AUTOSAR XML (schema 4-3-0)
standard types defined: UINT8, UINT16, UINT32, UINT64, SINT8, SINT16, SINT32, FLOAT32, FLOAT64
package /Pkg_ErrorMgrSat_2_1_B/ComponentTypes
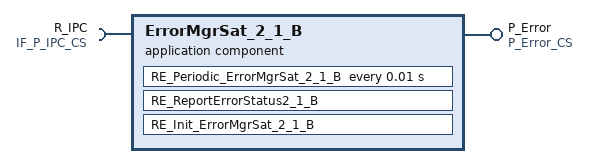
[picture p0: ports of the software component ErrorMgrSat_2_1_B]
  application sw component type ErrorMgrSat_2_1_B
    provide port P_Error: server-com-spec{operation=ReportErrorStatus2_1_B, queue-length=1}, provided-interface=P_Error_CS
    require port R_IPC: client-com-spec=IPC_Write_v, required-interface=IF_P_IPC_CS
    behavior ErrorMgrSat_2_1_B_InternalBehavior: handle-termination-and-restart=NO-SUPPORT
      timing event TMT_RE_Periodic_ErrorMgrSat_2_1_B: start-on-event=RE_Periodic_ErrorMgrSat_2_1_B, period=0.01
      operation invoked event OIT_RE_ReportErrorStatus2_1_B_P_Error_ReportErrorStatus2_1_B: start-on-event=RE_ReportErrorStatus2_1_B, operation=P_Error.ReportErrorStatus2_1_B
      init event InitEvent: start-on-event=RE_Init_ErrorMgrSat_2_1_B
      port-api-options:
        enable-take-address=false, indirect-api=false, port=P_Error
        enable-take-address=false, indirect-api=false, port=R_IPC
      runnable RE_Periodic_ErrorMgrSat_2_1_B  # Periodic Runnable of Satellite
        sync call SC_R_IPC_IPC_Write_v: operation=R_IPC.IPC_Write_v, timeout=0
      runnable RE_ReportErrorStatus2_1_B: can-be-invoked-concurrently=true  # Server Runnable for handling the error reporting
      runnable RE_Init_ErrorMgrSat_2_1_B  # Init Runnable
  swc implementation ErrorMgrSat_2_1_B_Implementation: programming-language=C, vendor-id=0, behavior=ErrorMgrSat_2_1_B_InternalBehavior
    code-descriptors:
      code Default: artifact-descriptors=autosar-engineering-object={short-label=Default, category=SWSRC}
package /Pkg_ErrorMgrSat_2_1_B/ImplementationDataTypes
  30 x impl type, all with type-emitter=RTE:
    BOOL: implementation-data-type=boolean
    ErrorMgr_ErrorField: implementation-data-type=uint8
    Error1_0QM_arr: category=ARRAY
      element Elem_ErrorMgr_ErrorField: array-size=12, array-size-semantics=FIXED-SIZE, implementation-data-type=ErrorMgr_ErrorField
    Data1_0QM_arr: category=ARRAY
      element Elem_ErrorMgr_stAddData: array-size=12, array-size-semantics=FIXED-SIZE, implementation-data-type=ErrorMgr_stAddData
    Error1_0B_arr: category=ARRAY
      element Elem_ErrorMgr_ErrorField: array-size=400, array-size-semantics=FIXED-SIZE, implementation-data-type=ErrorMgr_ErrorField
    Data1_0B_arr: category=ARRAY
      element Elem_ErrorMgr_stAddData: array-size=400, array-size-semantics=FIXED-SIZE, implementation-data-type=ErrorMgr_stAddData
    Error2_0QM_arr: category=ARRAY
      element Elem_ErrorMgr_ErrorField: array-size=1, array-size-semantics=FIXED-SIZE, implementation-data-type=ErrorMgr_ErrorField
    Padding2_0QM_arr: category=ARRAY
      element Elem_ErrorMgr_ErrorField: array-size=3, array-size-semantics=FIXED-SIZE, implementation-data-type=ErrorMgr_ErrorField
    Data2_0QM_arr: category=ARRAY
      element Elem_ErrorMgr_stAddData: array-size=1, array-size-semantics=FIXED-SIZE, implementation-data-type=ErrorMgr_stAddData
    Error2_0B_arr: category=ARRAY
      element Elem_ErrorMgr_ErrorField: array-size=144, array-size-semantics=FIXED-SIZE, implementation-data-type=ErrorMgr_ErrorField
    Data2_0B_arr: category=ARRAY
      element Elem_ErrorMgr_stAddData: array-size=144, array-size-semantics=FIXED-SIZE, implementation-data-type=ErrorMgr_stAddData
    Error2_1QM_arr: category=ARRAY
      element Elem_ErrorMgr_ErrorField: array-size=1, array-size-semantics=FIXED-SIZE, implementation-data-type=ErrorMgr_ErrorField
    Padding2_1QM_arr: category=ARRAY
      element Elem_ErrorMgr_ErrorField: array-size=3, array-size-semantics=FIXED-SIZE, implementation-data-type=ErrorMgr_ErrorField
    Data2_1QM_arr: category=ARRAY
      element Elem_ErrorMgr_stAddData: array-size=1, array-size-semantics=FIXED-SIZE, implementation-data-type=ErrorMgr_stAddData
    Error2_1B_arr: category=ARRAY
      element Elem_ErrorMgr_ErrorField: array-size=548, array-size-semantics=FIXED-SIZE, implementation-data-type=ErrorMgr_ErrorField
    Data2_1B_arr: category=ARRAY
      element Elem_ErrorMgr_stAddData: array-size=548, array-size-semantics=FIXED-SIZE, implementation-data-type=ErrorMgr_stAddData
    ErrorQNXQM_arr: category=ARRAY
      element Elem_ErrorMgr_ErrorField: array-size=1, array-size-semantics=FIXED-SIZE, implementation-data-type=ErrorMgr_ErrorField
    PaddingQNXQM_arr: category=ARRAY
      element Elem_ErrorMgr_ErrorField: array-size=3, array-size-semantics=FIXED-SIZE, implementation-data-type=ErrorMgr_ErrorField
    DataQNXQM_arr: category=ARRAY
      element Elem_ErrorMgr_stAddData: array-size=1, array-size-semantics=FIXED-SIZE, implementation-data-type=ErrorMgr_stAddData
    ErrorQNXB_arr: category=ARRAY
      element Elem_ErrorMgr_ErrorField: array-size=8, array-size-semantics=FIXED-SIZE, implementation-data-type=ErrorMgr_ErrorField
    DataQNXB_arr: category=ARRAY
      element Elem_ErrorMgr_stAddData: array-size=8, array-size-semantics=FIXED-SIZE, implementation-data-type=ErrorMgr_stAddData
    AdditionalData_arr: category=ARRAY
      element Elem_uint8: array-size=4, array-size-semantics=FIXED-SIZE, implementation-data-type=uint8
    ErrorMgr_enErrorNo: compu {556=ErrorMgr_Error_SENSOR1_OpenCkt_Fault, 557=ErrorMgr_Error_SENSOR2_OpenCkt_Fault, 558=ErrorMgr_Error_SENSOR3_OpenCkt_Fault, 559=ErrorMgr_Error_SENSOR4_OpenCkt_Fault, 560=ErrorMgr_Error_SENSOR5_OpenCkt_Fault, 561=ErrorMgr_Error_SENSOR6_OpenCkt_Fault, 562=ErrorMgr_Error_SENSOR7_OpenCkt_Fault, 563=ErrorMgr_Error_SENSOR8_OpenCkt_Fault, 564=ErrorMgr_Error_SENSOR9_OpenCkt_Fault, 565=ErrorMgr_Error_SENSOR10_OpenCkt_Fault, 566=ErrorMgr_Error_SENSOR11_OpenCkt_Fault, 567=ErrorMgr_Error_SENSOR12_OpenCkt_Fault, 568=ErrorMgr_Error_SENSOR1_USS_Power_Lost_Fault, 569=ErrorMgr_Error_SENSOR2_USS_Power_Lost_Fault, 570=ErrorMgr_Error_SENSOR3_USS_Power_Lost_Fault, 571=ErrorMgr_Error_SENSOR4_USS_Power_Lost_Fault, 572=ErrorMgr_Error_SENSOR5_USS_Power_Lost_Fault, 573=ErrorMgr_Error_SENSOR6_USS_Power_Lost_Fault, 574=ErrorMgr_Error_SENSOR7_USS_Power_Lost_Fault, 575=ErrorMgr_Error_SENSOR8_USS_Power_Lost_Fault, 576=ErrorMgr_Error_SENSOR9_USS_Power_Lost_Fault, 577=ErrorMgr_Error_SENSOR10_USS_Power_Lost_Fault, 578=ErrorMgr_Error_SENSOR11_USS_Power_Lost_Fault, 579=ErrorMgr_Error_SENSOR12_USS_Power_Lost_Fault, 580=ErrorMgr_Error_USS_M_F_short_to_GND, 581=ErrorMgr_Error_USS_M_F_voltage_OOR_Low, 582=ErrorMgr_Error_USS_M_R_short_to_GND, 583=ErrorMgr_Error_USS_M_R_voltage_OOR_Low, 584=ErrorMgr_Error_USS_Cal_Data_Fault, 585=ErrorMgr_Error_SENSOR1_USS_SWFirmWr_MisMatch, 586=ErrorMgr_Error_SENSOR2_USS_SWFirmWr_MisMatch, 587=ErrorMgr_Error_SENSOR3_USS_SWFirmWr_MisMatch, 588=ErrorMgr_Error_SENSOR4_USS_SWFirmWr_MisMatch, 589=ErrorMgr_Error_SENSOR5_USS_SWFirmWr_MisMatch, 590=ErrorMgr_Error_SENSOR6_USS_SWFirmWr_MisMatch, 591=ErrorMgr_Error_SENSOR7_USS_SWFirmWr_MisMatch, 592=ErrorMgr_Error_SENSOR8_USS_SWFirmWr_MisMatch, 593=ErrorMgr_Error_SENSOR9_USS_SWFirmWr_MisMatch, 594=ErrorMgr_Error_SENSOR10_USS_SWFirmWr_MisMatch, 595=ErrorMgr_Error_SENSOR11_USS_SWFirmWr_MisMatch, 596=ErrorMgr_Error_SENSOR12_USS_SWFirmWr_MisMatch, 597=ErrorMgr_Error_SENSOR1_USS_Sensor_Blockage, 598=ErrorMgr_Error_SENSOR2_USS_Sensor_Blockage, 599=ErrorMgr_Error_SENSOR3_USS_Sensor_Blockage, 600=ErrorMgr_Error_SENSOR4_USS_Sensor_Blockage, 601=ErrorMgr_Error_SENSOR5_USS_Sensor_Blockage, 602=ErrorMgr_Error_SENSOR6_USS_Sensor_Blockage, 603=ErrorMgr_Error_SENSOR7_USS_Sensor_Blockage, 604=ErrorMgr_Error_SENSOR8_USS_Sensor_Blockage, 605=ErrorMgr_Error_SENSOR9_USS_Sensor_Blockage, 606=ErrorMgr_Error_SENSOR10_USS_Sensor_Blockage, 607=ErrorMgr_Error_SENSOR11_USS_Sensor_Blockage, 608=ErrorMgr_Error_SENSOR12_USS_Sensor_Blockage, 609=ErrorMgr_Error_USS_M_F_Short_to_Bat, 610=ErrorMgr_Error_USS_M_F_voltage_OOR_High, 611=ErrorMgr_Error_USS_M_R_Short_to_Bat, 612=ErrorMgr_Error_USS_M_R_voltage_OOR_High, 613=ErrorMgr_Error_SysIntFault_MCU_USS_MASTER_internal_failure_RAM_BIST_failure, 614=ErrorMgr_Error_SysIntFault_MCU_USS_MASTER_internal_failure_FSM_RESET, 615=ErrorMgr_Error_SysIntFault_MCU_USS_MASTER_internal_failure_VDSIUV, 616=ErrorMgr_Error_SysIntFault_MCU_USS_MASTER_internal_failure_VCCUV, 617=ErrorMgr_Error_SysIntFault_MCU_USS_MASTER_ECU_COMM_ERR, 618=ErrorMgr_Error_SysIntFault_MCU_USS_MASTER_INTB_pin_low_CLKREF_failure, 619=ErrorMgr_Error_SysIntFault_MCU_USS_MASTER_DSI_Overtemperature_error, 620=ErrorMgr_Error_SysIntFault_MCU_USS_MASTER_DSI3_Safety_critical_registers_mismatch, 621=ErrorMgr_Error_SysIntFault_MCU_USS_MASTER_DSI_IRQ_STAT_CRC_ERR, 622=ErrorMgr_Error_SysIntFault_MCU_USS_MASTER_ECU_SPI_DMA_ERR, 623=ErrorMgr_Error_SysIntFault_MCU_USS_MASTER_ECU_CFG_SENSOR_ERR, 624=ErrorMgr_Error_SysIntFault_MCU_USS_MASTER_ECU_GPIO_INT_INITIAL_ERR, 625=ErrorMgr_Error_SysIntFault_MCU_USS_MASTER_ECU_PIN_INITIAL_ERR, 626=ErrorMgr_Error_SysIntFault_MCU_USS_MASTER_ECU_DSI_CLOCK_INITIAL_ERR, 627=ErrorMgr_Error_SysIntFault_MCU_USS_MASTER_ECU_SPI_INITIAL_ERR, 628=ErrorMgr_Error_SysIntFault_MCU_USS_MASTER_ECU_USS_POWER_ON_ERR, 629=ErrorMgr_Error_SysIntFault_MCU_USS_MASTER_ECU_DSI_RFC_ERR, 630=ErrorMgr_Error_SysIntFault_MCU_USS_MASTER_Front_OC_ERR, 631=ErrorMgr_Error_SysIntFault_MCU_USS_MASTER_Front_DSI_Undervoltage_error, 632=ErrorMgr_Error_SysIntFault_MCU_USS_MASTER_Rear_OC_ERR, 633=ErrorMgr_Error_SysIntFault_MCU_USS_MASTER_Rear_DSI_Undervoltage_error, 634=ErrorMgr_Error_SysIntFault_USS_SENSOR1_FLG_SIGNAL_PATH_FAILURE, 635=ErrorMgr_Error_SysIntFault_USS_SENSOR1_Vref_out_of_range, 636=ErrorMgr_Error_SysIntFault_USS_SENSOR1_VREF_OTP_out_of_range, 637=ErrorMgr_Error_SysIntFault_USS_SENSOR1_VDDD_out_of_range, 638=ErrorMgr_Error_SysIntFault_USS_SENSOR1_DRV1_FAILURE_DURING_BURST, 639=ErrorMgr_Error_SysIntFault_USS_SENSOR1_DRV2_FAILURE_DURING_BURST, 640=ErrorMgr_Error_SysIntFault_USS_SENSOR1_DRVS_FAILURE_DURING_BURST, 641=ErrorMgr_Error_SysIntFault_USS_SENSOR1_NOISE_DURING_BURST, 642=ErrorMgr_Error_SysIntFault_USS_SENSOR1_DSP_Config_register_mismatch, 643=ErrorMgr_Error_SysIntFault_USS_SENSOR1_CPU_Config_register_mismatch, 644=ErrorMgr_Error_SysIntFault_USS_SENSOR1_RECEIVED_COMMAND_INVALID, 645=ErrorMgr_Error_SysIntFault_USS_SENSOR1_WD_COUNTER_DESYNC, 646=ErrorMgr_Error_SysIntFault_USS_SENSOR1_WD_CLOCK_FAIL, 647=ErrorMgr_Error_SysIntFault_USS_SENSOR1_SYNCHRONISATION_COUNTER_ERROR_DETECTED, 648=ErrorMgr_Error_SysIntFault_USS_SENSOR1_GET_DRV_FREQUENCY_FAILURE, 649=ErrorMgr_Error_SysIntFault_USS_SENSOR1_RING_COMPARATOR_ZERO, 650=ErrorMgr_Error_SysIntFault_USS_SENSOR1_VTANK_overvoltage_burst_status_failure, 651=ErrorMgr_Error_SysIntFault_USS_SENSOR1_BURST_ABORT_DURING_BURST, 652=ErrorMgr_Error_SysIntFault_USS_SENSOR1_VTANK_OVERVOLTAGE, 653=ErrorMgr_Error_SysIntFault_USS_SENSOR1_VTANK_UNDERVOLTAGE, 654=ErrorMgr_Error_SysIntFault_USS_SENSOR1_VSUP_OVER_VOLTAGE, 655=ErrorMgr_Error_SysIntFault_USS_SENSOR1_VSUP_UNDER_VOLTAGE, 656=ErrorMgr_Error_SysIntFault_USS_SENSOR1_Temparature_out_of_range_error, 657=ErrorMgr_Error_SysIntFault_USS_SENSOR1_SRAM_Parity_error, 658=ErrorMgr_Error_SysIntFault_USS_SENSOR1_CRC_BLOCK_CFG1, 659=ErrorMgr_Error_SysIntFault_USS_SENSOR1_CRC_BLOCK_CFG2, 660=ErrorMgr_Error_SysIntFault_USS_SENSOR1_CRC_BLOCK_MFG1, 661=ErrorMgr_Error_SysIntFault_USS_SENSOR1_CRC_BLOCK_MFG2, 662=ErrorMgr_Error_SysIntFault_USS_SENSOR1_CRC_OP_MODE1, 663=ErrorMgr_Error_SysIntFault_USS_SENSOR1_CRC_OP_MODE2, 664=ErrorMgr_Error_SysIntFault_USS_SENSOR1_CRC_MISMATCH_IN_OTP, 665=ErrorMgr_Error_SysIntFault_USS_SENSOR1_CRC_MISTMATCH_IN_EEPROM_A1, 666=ErrorMgr_Error_SysIntFault_USS_SENSOR1_CRC_MISTMATCH_IN_EEPROM_A2, 667=ErrorMgr_Error_SysIntFault_USS_SENSOR1_BAD_RING_TIME, 668=ErrorMgr_Error_SysIntFault_USS_SENSOR1_SNR_OPMODE_ERROR, 669=ErrorMgr_Error_SysIntFault_USS_SENSOR1_SNR_SETUP_SENSOR_FAIL, 670=ErrorMgr_Error_SysIntFault_USS_SENSOR1_GET_RING_FREQUENCY_FAILURE, 671=ErrorMgr_Error_SysIntFault_USS_SENSOR1_ADA_MEASURE_TIMEOUT, 672=ErrorMgr_Error_SysIntFault_USS_SENSOR1_PROGRAM_EEPROM, 673=ErrorMgr_Error_SysIntFault_USS_SENSOR2_FLG_SIGNAL_PATH_FAILURE, 674=ErrorMgr_Error_SysIntFault_USS_SENSOR2_Vref_out_of_range, 675=ErrorMgr_Error_SysIntFault_USS_SENSOR2_VREF_OTP_out_of_range, 676=ErrorMgr_Error_SysIntFault_USS_SENSOR2_VDDD_out_of_range, 677=ErrorMgr_Error_SysIntFault_USS_SENSOR2_DRV1_FAILURE_DURING_BURST, 678=ErrorMgr_Error_SysIntFault_USS_SENSOR2_DRV2_FAILURE_DURING_BURST, 679=ErrorMgr_Error_SysIntFault_USS_SENSOR2_DRVS_FAILURE_DURING_BURST, 680=ErrorMgr_Error_SysIntFault_USS_SENSOR2_NOISE_DURING_BURST, 681=ErrorMgr_Error_SysIntFault_USS_SENSOR2_DSP_Config_register_mismatch, 682=ErrorMgr_Error_SysIntFault_USS_SENSOR2_CPU_Config_register_mismatch, 683=ErrorMgr_Error_SysIntFault_USS_SENSOR2_RECEIVED_COMMAND_INVALID, 684=ErrorMgr_Error_SysIntFault_USS_SENSOR2_WD_COUNTER_DESYNC, 685=ErrorMgr_Error_SysIntFault_USS_SENSOR2_WD_CLOCK_FAIL, 686=ErrorMgr_Error_SysIntFault_USS_SENSOR2_SYNCHRONISATION_COUNTER_ERROR_DETECTED, 687=ErrorMgr_Error_SysIntFault_USS_SENSOR2_GET_DRV_FREQUENCY_FAILURE, 688=ErrorMgr_Error_SysIntFault_USS_SENSOR2_RING_COMPARATOR_ZERO, 689=ErrorMgr_Error_SysIntFault_USS_SENSOR2_VTANK_overvoltage_burst_status_failure, 690=ErrorMgr_Error_SysIntFault_USS_SENSOR2_BURST_ABORT_DURING_BURST, 691=ErrorMgr_Error_SysIntFault_USS_SENSOR2_VTANK_OVERVOLTAGE, 692=ErrorMgr_Error_SysIntFault_USS_SENSOR2_VTANK_UNDERVOLTAGE, 693=ErrorMgr_Error_SysIntFault_USS_SENSOR2_VSUP_OVER_VOLTAGE, 694=ErrorMgr_Error_SysIntFault_USS_SENSOR2_VSUP_UNDER_VOLTAGE, 695=ErrorMgr_Error_SysIntFault_USS_SENSOR2_Temparature_out_of_range_error, 696=ErrorMgr_Error_SysIntFault_USS_SENSOR2_SRAM_Parity_error, 697=ErrorMgr_Error_SysIntFault_USS_SENSOR2_CRC_BLOCK_CFG1, 698=ErrorMgr_Error_SysIntFault_USS_SENSOR2_CRC_BLOCK_CFG2, 699=ErrorMgr_Error_SysIntFault_USS_SENSOR2_CRC_BLOCK_MFG1, 700=ErrorMgr_Error_SysIntFault_USS_SENSOR2_CRC_BLOCK_MFG2, 701=ErrorMgr_Error_SysIntFault_USS_SENSOR2_CRC_OP_MODE1, 702=ErrorMgr_Error_SysIntFault_USS_SENSOR2_CRC_OP_MODE2, 703=ErrorMgr_Error_SysIntFault_USS_SENSOR2_CRC_MISMATCH_IN_OTP, 704=ErrorMgr_Error_SysIntFault_USS_SENSOR2_CRC_MISTMATCH_IN_EEPROM_A1, 705=ErrorMgr_Error_SysIntFault_USS_SENSOR2_CRC_MISTMATCH_IN_EEPROM_A2, 706=ErrorMgr_Error_SysIntFault_USS_SENSOR2_BAD_RING_TIME, 707=ErrorMgr_Error_SysIntFault_USS_SENSOR2_SNR_OPMODE_ERROR, 708=ErrorMgr_Error_SysIntFault_USS_SENSOR2_SNR_SETUP_SENSOR_FAIL, 709=ErrorMgr_Error_SysIntFault_USS_SENSOR2_GET_RING_FREQUENCY_FAILURE, 710=ErrorMgr_Error_SysIntFault_USS_SENSOR2_ADA_MEASURE_TIMEOUT, 711=ErrorMgr_Error_SysIntFault_USS_SENSOR2_PROGRAM_EEPROM, 712=ErrorMgr_Error_SysIntFault_USS_SENSOR3_FLG_SIGNAL_PATH_FAILURE, 713=ErrorMgr_Error_SysIntFault_USS_SENSOR3_Vref_out_of_range, 714=ErrorMgr_Error_SysIntFault_USS_SENSOR3_VREF_OTP_out_of_range, 715=ErrorMgr_Error_SysIntFault_USS_SENSOR3_VDDD_out_of_range, 716=ErrorMgr_Error_SysIntFault_USS_SENSOR3_DRV1_FAILURE_DURING_BURST, 717=ErrorMgr_Error_SysIntFault_USS_SENSOR3_DRV2_FAILURE_DURING_BURST, 718=ErrorMgr_Error_SysIntFault_USS_SENSOR3_DRVS_FAILURE_DURING_BURST, 719=ErrorMgr_Error_SysIntFault_USS_SENSOR3_NOISE_DURING_BURST, 720=ErrorMgr_Error_SysIntFault_USS_SENSOR3_DSP_Config_register_mismatch, 721=ErrorMgr_Error_SysIntFault_USS_SENSOR3_CPU_Config_register_mismatch, 722=ErrorMgr_Error_SysIntFault_USS_SENSOR3_RECEIVED_COMMAND_INVALID, 723=ErrorMgr_Error_SysIntFault_USS_SENSOR3_WD_COUNTER_DESYNC, 724=ErrorMgr_Error_SysIntFault_USS_SENSOR3_WD_CLOCK_FAIL, 725=ErrorMgr_Error_SysIntFault_USS_SENSOR3_SYNCHRONISATION_COUNTER_ERROR_DETECTED, 726=ErrorMgr_Error_SysIntFault_USS_SENSOR3_GET_DRV_FREQUENCY_FAILURE, 727=ErrorMgr_Error_SysIntFault_USS_SENSOR3_RING_COMPARATOR_ZERO, 728=ErrorMgr_Error_SysIntFault_USS_SENSOR3_VTANK_overvoltage_burst_status_failure, 729=ErrorMgr_Error_SysIntFault_USS_SENSOR3_BURST_ABORT_DURING_BURST, 730=ErrorMgr_Error_SysIntFault_USS_SENSOR3_VTANK_OVERVOLTAGE, 731=ErrorMgr_Error_SysIntFault_USS_SENSOR3_VTANK_UNDERVOLTAGE, 732=ErrorMgr_Error_SysIntFault_USS_SENSOR3_VSUP_OVER_VOLTAGE, 733=ErrorMgr_Error_SysIntFault_USS_SENSOR3_VSUP_UNDER_VOLTAGE, 734=ErrorMgr_Error_SysIntFault_USS_SENSOR3_Temparature_out_of_range_error, 735=ErrorMgr_Error_SysIntFault_USS_SENSOR3_SRAM_Parity_error, 736=ErrorMgr_Error_SysIntFault_USS_SENSOR3_CRC_BLOCK_CFG1, 737=ErrorMgr_Error_SysIntFault_USS_SENSOR3_CRC_BLOCK_CFG2, 738=ErrorMgr_Error_SysIntFault_USS_SENSOR3_CRC_BLOCK_MFG1, 739=ErrorMgr_Error_SysIntFault_USS_SENSOR3_CRC_BLOCK_MFG2, 740=ErrorMgr_Error_SysIntFault_USS_SENSOR3_CRC_OP_MODE1, 741=ErrorMgr_Error_SysIntFault_USS_SENSOR3_CRC_OP_MODE2, 742=ErrorMgr_Error_SysIntFault_USS_SENSOR3_CRC_MISMATCH_IN_OTP, 743=ErrorMgr_Error_SysIntFault_USS_SENSOR3_CRC_MISTMATCH_IN_EEPROM_A1, 744=ErrorMgr_Error_SysIntFault_USS_SENSOR3_CRC_MISTMATCH_IN_EEPROM_A2, 745=ErrorMgr_Error_SysIntFault_USS_SENSOR3_BAD_RING_TIME, 746=ErrorMgr_Error_SysIntFault_USS_SENSOR3_SNR_OPMODE_ERROR, 747=ErrorMgr_Error_SysIntFault_USS_SENSOR3_SNR_SETUP_SENSOR_FAIL, 748=ErrorMgr_Error_SysIntFault_USS_SENSOR3_GET_RING_FREQUENCY_FAILURE, 749=ErrorMgr_Error_SysIntFault_USS_SENSOR3_ADA_MEASURE_TIMEOUT, 750=ErrorMgr_Error_SysIntFault_USS_SENSOR3_PROGRAM_EEPROM, 751=ErrorMgr_Error_SysIntFault_USS_SENSOR4_FLG_SIGNAL_PATH_FAILURE, 752=ErrorMgr_Error_SysIntFault_USS_SENSOR4_Vref_out_of_range, 753=ErrorMgr_Error_SysIntFault_USS_SENSOR4_VREF_OTP_out_of_range, 754=ErrorMgr_Error_SysIntFault_USS_SENSOR4_VDDD_out_of_range, 755=ErrorMgr_Error_SysIntFault_USS_SENSOR4_DRV1_FAILURE_DURING_BURST, 756=ErrorMgr_Error_SysIntFault_USS_SENSOR4_DRV2_FAILURE_DURING_BURST, 757=ErrorMgr_Error_SysIntFault_USS_SENSOR4_DRVS_FAILURE_DURING_BURST, 758=ErrorMgr_Error_SysIntFault_USS_SENSOR4_NOISE_DURING_BURST, 759=ErrorMgr_Error_SysIntFault_USS_SENSOR4_DSP_Config_register_mismatch, 760=ErrorMgr_Error_SysIntFault_USS_SENSOR4_CPU_Config_register_mismatch, 761=ErrorMgr_Error_SysIntFault_USS_SENSOR4_RECEIVED_COMMAND_INVALID, 762=ErrorMgr_Error_SysIntFault_USS_SENSOR4_WD_COUNTER_DESYNC, 763=ErrorMgr_Error_SysIntFault_USS_SENSOR4_WD_CLOCK_FAIL, 764=ErrorMgr_Error_SysIntFault_USS_SENSOR4_SYNCHRONISATION_COUNTER_ERROR_DETECTED, 765=ErrorMgr_Error_SysIntFault_USS_SENSOR4_GET_DRV_FREQUENCY_FAILURE, 766=ErrorMgr_Error_SysIntFault_USS_SENSOR4_RING_COMPARATOR_ZERO, 767=ErrorMgr_Error_SysIntFault_USS_SENSOR4_VTANK_overvoltage_burst_status_failure, 768=ErrorMgr_Error_SysIntFault_USS_SENSOR4_BURST_ABORT_DURING_BURST, 769=ErrorMgr_Error_SysIntFault_USS_SENSOR4_VTANK_OVERVOLTAGE, 770=ErrorMgr_Error_SysIntFault_USS_SENSOR4_VTANK_UNDERVOLTAGE, 771=ErrorMgr_Error_SysIntFault_USS_SENSOR4_VSUP_OVER_VOLTAGE, 772=ErrorMgr_Error_SysIntFault_USS_SENSOR4_VSUP_UNDER_VOLTAGE, 773=ErrorMgr_Error_SysIntFault_USS_SENSOR4_Temparature_out_of_range_error, 774=ErrorMgr_Error_SysIntFault_USS_SENSOR4_SRAM_Parity_error, 775=ErrorMgr_Error_SysIntFault_USS_SENSOR4_CRC_BLOCK_CFG1, 776=ErrorMgr_Error_SysIntFault_USS_SENSOR4_CRC_BLOCK_CFG2, 777=ErrorMgr_Error_SysIntFault_USS_SENSOR4_CRC_BLOCK_MFG1, 778=ErrorMgr_Error_SysIntFault_USS_SENSOR4_CRC_BLOCK_MFG2, 779=ErrorMgr_Error_SysIntFault_USS_SENSOR4_CRC_OP_MODE1, 780=ErrorMgr_Error_SysIntFault_USS_SENSOR4_CRC_OP_MODE2, 781=ErrorMgr_Error_SysIntFault_USS_SENSOR4_CRC_MISMATCH_IN_OTP, 782=ErrorMgr_Error_SysIntFault_USS_SENSOR4_CRC_MISTMATCH_IN_EEPROM_A1, 783=ErrorMgr_Error_SysIntFault_USS_SENSOR4_CRC_MISTMATCH_IN_EEPROM_A2, 784=ErrorMgr_Error_SysIntFault_USS_SENSOR4_BAD_RING_TIME, 785=ErrorMgr_Error_SysIntFault_USS_SENSOR4_SNR_OPMODE_ERROR, 786=ErrorMgr_Error_SysIntFault_USS_SENSOR4_SNR_SETUP_SENSOR_FAIL, 787=ErrorMgr_Error_SysIntFault_USS_SENSOR4_GET_RING_FREQUENCY_FAILURE, 788=ErrorMgr_Error_SysIntFault_USS_SENSOR4_ADA_MEASURE_TIMEOUT, 789=ErrorMgr_Error_SysIntFault_USS_SENSOR4_PROGRAM_EEPROM, 790=ErrorMgr_Error_SysIntFault_USS_SENSOR5_FLG_SIGNAL_PATH_FAILURE, 791=ErrorMgr_Error_SysIntFault_USS_SENSOR5_Vref_out_of_range, 792=ErrorMgr_Error_SysIntFault_USS_SENSOR5_VREF_OTP_out_of_range, 793=ErrorMgr_Error_SysIntFault_USS_SENSOR5_VDDD_out_of_range, 794=ErrorMgr_Error_SysIntFault_USS_SENSOR5_DRV1_FAILURE_DURING_BURST, 795=ErrorMgr_Error_SysIntFault_USS_SENSOR5_DRV2_FAILURE_DURING_BURST, 796=ErrorMgr_Error_SysIntFault_USS_SENSOR5_DRVS_FAILURE_DURING_BURST, 797=ErrorMgr_Error_SysIntFault_USS_SENSOR5_NOISE_DURING_BURST, 798=ErrorMgr_Error_SysIntFault_USS_SENSOR5_DSP_Config_register_mismatch, 799=ErrorMgr_Error_SysIntFault_USS_SENSOR5_CPU_Config_register_mismatch, 800=ErrorMgr_Error_SysIntFault_USS_SENSOR5_RECEIVED_COMMAND_INVALID, 801=ErrorMgr_Error_SysIntFault_USS_SENSOR5_WD_COUNTER_DESYNC, 802=ErrorMgr_Error_SysIntFault_USS_SENSOR5_WD_CLOCK_FAIL, 803=ErrorMgr_Error_SysIntFault_USS_SENSOR5_SYNCHRONISATION_COUNTER_ERROR_DETECTED, 804=ErrorMgr_Error_SysIntFault_USS_SENSOR5_GET_DRV_FREQUENCY_FAILURE, 805=ErrorMgr_Error_SysIntFault_USS_SENSOR5_RING_COMPARATOR_ZERO, 806=ErrorMgr_Error_SysIntFault_USS_SENSOR5_VTANK_overvoltage_burst_status_failure, 807=ErrorMgr_Error_SysIntFault_USS_SENSOR5_BURST_ABORT_DURING_BURST, 808=ErrorMgr_Error_SysIntFault_USS_SENSOR5_VTANK_OVERVOLTAGE, 809=ErrorMgr_Error_SysIntFault_USS_SENSOR5_VTANK_UNDERVOLTAGE, 810=ErrorMgr_Error_SysIntFault_USS_SENSOR5_VSUP_OVER_VOLTAGE, 811=ErrorMgr_Error_SysIntFault_USS_SENSOR5_VSUP_UNDER_VOLTAGE, 812=ErrorMgr_Error_SysIntFault_USS_SENSOR5_Temparature_out_of_range_error, 813=ErrorMgr_Error_SysIntFault_USS_SENSOR5_SRAM_Parity_error, 814=ErrorMgr_Error_SysIntFault_USS_SENSOR5_CRC_BLOCK_CFG1, 815=ErrorMgr_Error_SysIntFault_USS_SENSOR5_CRC_BLOCK_CFG2, 816=ErrorMgr_Error_SysIntFault_USS_SENSOR5_CRC_BLOCK_MFG1, 817=ErrorMgr_Error_SysIntFault_USS_SENSOR5_CRC_BLOCK_MFG2, 818=ErrorMgr_Error_SysIntFault_USS_SENSOR5_CRC_OP_MODE1, 819=ErrorMgr_Error_SysIntFault_USS_SENSOR5_CRC_OP_MODE2, 820=ErrorMgr_Error_SysIntFault_USS_SENSOR5_CRC_MISMATCH_IN_OTP, 821=ErrorMgr_Error_SysIntFault_USS_SENSOR5_CRC_MISTMATCH_IN_EEPROM_A1, 822=ErrorMgr_Error_SysIntFault_USS_SENSOR5_CRC_MISTMATCH_IN_EEPROM_A2, 823=ErrorMgr_Error_SysIntFault_USS_SENSOR5_BAD_RING_TIME, 824=ErrorMgr_Error_SysIntFault_USS_SENSOR5_SNR_OPMODE_ERROR, 825=ErrorMgr_Error_SysIntFault_USS_SENSOR5_SNR_SETUP_SENSOR_FAIL, 826=ErrorMgr_Error_SysIntFault_USS_SENSOR5_GET_RING_FREQUENCY_FAILURE, 827=ErrorMgr_Error_SysIntFault_USS_SENSOR5_ADA_MEASURE_TIMEOUT, 828=ErrorMgr_Error_SysIntFault_USS_SENSOR5_PROGRAM_EEPROM, 829=ErrorMgr_Error_SysIntFault_USS_SENSOR6_FLG_SIGNAL_PATH_FAILURE, 830=ErrorMgr_Error_SysIntFault_USS_SENSOR6_Vref_out_of_range, 831=ErrorMgr_Error_SysIntFault_USS_SENSOR6_VREF_OTP_out_of_range, 832=ErrorMgr_Error_SysIntFault_USS_SENSOR6_VDDD_out_of_range, 833=ErrorMgr_Error_SysIntFault_USS_SENSOR6_DRV1_FAILURE_DURING_BURST, 834=ErrorMgr_Error_SysIntFault_USS_SENSOR6_DRV2_FAILURE_DURING_BURST, 835=ErrorMgr_Error_SysIntFault_USS_SENSOR6_DRVS_FAILURE_DURING_BURST, 836=ErrorMgr_Error_SysIntFault_USS_SENSOR6_NOISE_DURING_BURST, 837=ErrorMgr_Error_SysIntFault_USS_SENSOR6_DSP_Config_register_mismatch, 838=ErrorMgr_Error_SysIntFault_USS_SENSOR6_CPU_Config_register_mismatch, 839=ErrorMgr_Error_SysIntFault_USS_SENSOR6_RECEIVED_COMMAND_INVALID, 840=ErrorMgr_Error_SysIntFault_USS_SENSOR6_WD_COUNTER_DESYNC, 841=ErrorMgr_Error_SysIntFault_USS_SENSOR6_WD_CLOCK_FAIL, 842=ErrorMgr_Error_SysIntFault_USS_SENSOR6_SYNCHRONISATION_COUNTER_ERROR_DETECTED, 843=ErrorMgr_Error_SysIntFault_USS_SENSOR6_GET_DRV_FREQUENCY_FAILURE, 844=ErrorMgr_Error_SysIntFault_USS_SENSOR6_RING_COMPARATOR_ZERO, 845=ErrorMgr_Error_SysIntFault_USS_SENSOR6_VTANK_overvoltage_burst_status_failure, 846=ErrorMgr_Error_SysIntFault_USS_SENSOR6_BURST_ABORT_DURING_BURST, 847=ErrorMgr_Error_SysIntFault_USS_SENSOR6_VTANK_OVERVOLTAGE, 848=ErrorMgr_Error_SysIntFault_USS_SENSOR6_VTANK_UNDERVOLTAGE, 849=ErrorMgr_Error_SysIntFault_USS_SENSOR6_VSUP_OVER_VOLTAGE, 850=ErrorMgr_Error_SysIntFault_USS_SENSOR6_VSUP_UNDER_VOLTAGE, 851=ErrorMgr_Error_SysIntFault_USS_SENSOR6_Temparature_out_of_range_error, 852=ErrorMgr_Error_SysIntFault_USS_SENSOR6_SRAM_Parity_error, 853=ErrorMgr_Error_SysIntFault_USS_SENSOR6_CRC_BLOCK_CFG1, 854=ErrorMgr_Error_SysIntFault_USS_SENSOR6_CRC_BLOCK_CFG2, 855=ErrorMgr_Error_SysIntFault_USS_SENSOR6_CRC_BLOCK_MFG1, 856=ErrorMgr_Error_SysIntFault_USS_SENSOR6_CRC_BLOCK_MFG2, 857=ErrorMgr_Error_SysIntFault_USS_SENSOR6_CRC_OP_MODE1, 858=ErrorMgr_Error_SysIntFault_USS_SENSOR6_CRC_OP_MODE2, 859=ErrorMgr_Error_SysIntFault_USS_SENSOR6_CRC_MISMATCH_IN_OTP, 860=ErrorMgr_Error_SysIntFault_USS_SENSOR6_CRC_MISTMATCH_IN_EEPROM_A1, 861=ErrorMgr_Error_SysIntFault_USS_SENSOR6_CRC_MISTMATCH_IN_EEPROM_A2, 862=ErrorMgr_Error_SysIntFault_USS_SENSOR6_BAD_RING_TIME, 863=ErrorMgr_Error_SysIntFault_USS_SENSOR6_SNR_OPMODE_ERROR, 864=ErrorMgr_Error_SysIntFault_USS_SENSOR6_SNR_SETUP_SENSOR_FAIL, 865=ErrorMgr_Error_SysIntFault_USS_SENSOR6_GET_RING_FREQUENCY_FAILURE, 866=ErrorMgr_Error_SysIntFault_USS_SENSOR6_ADA_MEASURE_TIMEOUT, 867=ErrorMgr_Error_SysIntFault_USS_SENSOR6_PROGRAM_EEPROM, 868=ErrorMgr_Error_SysIntFault_USS_SENSOR7_FLG_SIGNAL_PATH_FAILURE, 869=ErrorMgr_Error_SysIntFault_USS_SENSOR7_Vref_out_of_range, 870=ErrorMgr_Error_SysIntFault_USS_SENSOR7_VREF_OTP_out_of_range, 871=ErrorMgr_Error_SysIntFault_USS_SENSOR7_VDDD_out_of_range, 872=ErrorMgr_Error_SysIntFault_USS_SENSOR7_DRV1_FAILURE_DURING_BURST, 873=ErrorMgr_Error_SysIntFault_USS_SENSOR7_DRV2_FAILURE_DURING_BURST, 874=ErrorMgr_Error_SysIntFault_USS_SENSOR7_DRVS_FAILURE_DURING_BURST, 875=ErrorMgr_Error_SysIntFault_USS_SENSOR7_NOISE_DURING_BURST, 876=ErrorMgr_Error_SysIntFault_USS_SENSOR7_DSP_Config_register_mismatch, 877=ErrorMgr_Error_SysIntFault_USS_SENSOR7_CPU_Config_register_mismatch, 878=ErrorMgr_Error_SysIntFault_USS_SENSOR7_RECEIVED_COMMAND_INVALID, 879=ErrorMgr_Error_SysIntFault_USS_SENSOR7_WD_COUNTER_DESYNC, 880=ErrorMgr_Error_SysIntFault_USS_SENSOR7_WD_CLOCK_FAIL, 881=ErrorMgr_Error_SysIntFault_USS_SENSOR7_SYNCHRONISATION_COUNTER_ERROR_DETECTED, 882=ErrorMgr_Error_SysIntFault_USS_SENSOR7_GET_DRV_FREQUENCY_FAILURE, 883=ErrorMgr_Error_SysIntFault_USS_SENSOR7_RING_COMPARATOR_ZERO, 884=ErrorMgr_Error_SysIntFault_USS_SENSOR7_VTANK_overvoltage_burst_status_failure, 885=ErrorMgr_Error_SysIntFault_USS_SENSOR7_BURST_ABORT_DURING_BURST, 886=ErrorMgr_Error_SysIntFault_USS_SENSOR7_VTANK_OVERVOLTAGE, 887=ErrorMgr_Error_SysIntFault_USS_SENSOR7_VTANK_UNDERVOLTAGE, 888=ErrorMgr_Error_SysIntFault_USS_SENSOR7_VSUP_OVER_VOLTAGE, 889=ErrorMgr_Error_SysIntFault_USS_SENSOR7_VSUP_UNDER_VOLTAGE, 890=ErrorMgr_Error_SysIntFault_USS_SENSOR7_Temparature_out_of_range_error, 891=ErrorMgr_Error_SysIntFault_USS_SENSOR7_SRAM_Parity_error, 892=ErrorMgr_Error_SysIntFault_USS_SENSOR7_CRC_BLOCK_CFG1, 893=ErrorMgr_Error_SysIntFault_USS_SENSOR7_CRC_BLOCK_CFG2, 894=ErrorMgr_Error_SysIntFault_USS_SENSOR7_CRC_BLOCK_MFG1, 895=ErrorMgr_Error_SysIntFault_USS_SENSOR7_CRC_BLOCK_MFG2, 896=ErrorMgr_Error_SysIntFault_USS_SENSOR7_CRC_OP_MODE1, 897=ErrorMgr_Error_SysIntFault_USS_SENSOR7_CRC_OP_MODE2, 898=ErrorMgr_Error_SysIntFault_USS_SENSOR7_CRC_MISMATCH_IN_OTP, 899=ErrorMgr_Error_SysIntFault_USS_SENSOR7_CRC_MISTMATCH_IN_EEPROM_A1, 900=ErrorMgr_Error_SysIntFault_USS_SENSOR7_CRC_MISTMATCH_IN_EEPROM_A2, 901=ErrorMgr_Error_SysIntFault_USS_SENSOR7_BAD_RING_TIME, 902=ErrorMgr_Error_SysIntFault_USS_SENSOR7_SNR_OPMODE_ERROR, 903=ErrorMgr_Error_SysIntFault_USS_SENSOR7_SNR_SETUP_SENSOR_FAIL, 904=ErrorMgr_Error_SysIntFault_USS_SENSOR7_GET_RING_FREQUENCY_FAILURE, 905=ErrorMgr_Error_SysIntFault_USS_SENSOR7_ADA_MEASURE_TIMEOUT, 906=ErrorMgr_Error_SysIntFault_USS_SENSOR7_PROGRAM_EEPROM, 907=ErrorMgr_Error_SysIntFault_USS_SENSOR8_FLG_SIGNAL_PATH_FAILURE, 908=ErrorMgr_Error_SysIntFault_USS_SENSOR8_Vref_out_of_range, 909=ErrorMgr_Error_SysIntFault_USS_SENSOR8_VREF_OTP_out_of_range, 910=ErrorMgr_Error_SysIntFault_USS_SENSOR8_VDDD_out_of_range, 911=ErrorMgr_Error_SysIntFault_USS_SENSOR8_DRV1_FAILURE_DURING_BURST, 912=ErrorMgr_Error_SysIntFault_USS_SENSOR8_DRV2_FAILURE_DURING_BURST, 913=ErrorMgr_Error_SysIntFault_USS_SENSOR8_DRVS_FAILURE_DURING_BURST, 914=ErrorMgr_Error_SysIntFault_USS_SENSOR8_NOISE_DURING_BURST, 915=ErrorMgr_Error_SysIntFault_USS_SENSOR8_DSP_Config_register_mismatch, 916=ErrorMgr_Error_SysIntFault_USS_SENSOR8_CPU_Config_register_mismatch, 917=ErrorMgr_Error_SysIntFault_USS_SENSOR8_RECEIVED_COMMAND_INVALID, 918=ErrorMgr_Error_SysIntFault_USS_SENSOR8_WD_COUNTER_DESYNC, 919=ErrorMgr_Error_SysIntFault_USS_SENSOR8_WD_CLOCK_FAIL, 920=ErrorMgr_Error_SysIntFault_USS_SENSOR8_SYNCHRONISATION_COUNTER_ERROR_DETECTED, 921=ErrorMgr_Error_SysIntFault_USS_SENSOR8_GET_DRV_FREQUENCY_FAILURE, 922=ErrorMgr_Error_SysIntFault_USS_SENSOR8_RING_COMPARATOR_ZERO, 923=ErrorMgr_Error_SysIntFault_USS_SENSOR8_VTANK_overvoltage_burst_status_failure, 924=ErrorMgr_Error_SysIntFault_USS_SENSOR8_BURST_ABORT_DURING_BURST, 925=ErrorMgr_Error_SysIntFault_USS_SENSOR8_VTANK_OVERVOLTAGE, 926=ErrorMgr_Error_SysIntFault_USS_SENSOR8_VTANK_UNDERVOLTAGE, 927=ErrorMgr_Error_SysIntFault_USS_SENSOR8_VSUP_OVER_VOLTAGE, 928=ErrorMgr_Error_SysIntFault_USS_SENSOR8_VSUP_UNDER_VOLTAGE, 929=ErrorMgr_Error_SysIntFault_USS_SENSOR8_Temparature_out_of_range_error, 930=ErrorMgr_Error_SysIntFault_USS_SENSOR8_SRAM_Parity_error, 931=ErrorMgr_Error_SysIntFault_USS_SENSOR8_CRC_BLOCK_CFG1, 932=ErrorMgr_Error_SysIntFault_USS_SENSOR8_CRC_BLOCK_CFG2, 933=ErrorMgr_Error_SysIntFault_USS_SENSOR8_CRC_BLOCK_MFG1, 934=ErrorMgr_Error_SysIntFault_USS_SENSOR8_CRC_BLOCK_MFG2, 935=ErrorMgr_Error_SysIntFault_USS_SENSOR8_CRC_OP_MODE1, 936=ErrorMgr_Error_SysIntFault_USS_SENSOR8_CRC_OP_MODE2, 937=ErrorMgr_Error_SysIntFault_USS_SENSOR8_CRC_MISMATCH_IN_OTP, 938=ErrorMgr_Error_SysIntFault_USS_SENSOR8_CRC_MISTMATCH_IN_EEPROM_A1, 939=ErrorMgr_Error_SysIntFault_USS_SENSOR8_CRC_MISTMATCH_IN_EEPROM_A2, 940=ErrorMgr_Error_SysIntFault_USS_SENSOR8_BAD_RING_TIME, 941=ErrorMgr_Error_SysIntFault_USS_SENSOR8_SNR_OPMODE_ERROR, 942=ErrorMgr_Error_SysIntFault_USS_SENSOR8_SNR_SETUP_SENSOR_FAIL, 943=ErrorMgr_Error_SysIntFault_USS_SENSOR8_GET_RING_FREQUENCY_FAILURE, 944=ErrorMgr_Error_SysIntFault_USS_SENSOR8_ADA_MEASURE_TIMEOUT, 945=ErrorMgr_Error_SysIntFault_USS_SENSOR8_PROGRAM_EEPROM, 946=ErrorMgr_Error_SysIntFault_USS_SENSOR9_FLG_SIGNAL_PATH_FAILURE, 947=ErrorMgr_Error_SysIntFault_USS_SENSOR9_Vref_out_of_range, 948=ErrorMgr_Error_SysIntFault_USS_SENSOR9_VREF_OTP_out_of_range, 949=ErrorMgr_Error_SysIntFault_USS_SENSOR9_VDDD_out_of_range, 950=ErrorMgr_Error_SysIntFault_USS_SENSOR9_DRV1_FAILURE_DURING_BURST, 951=ErrorMgr_Error_SysIntFault_USS_SENSOR9_DRV2_FAILURE_DURING_BURST, 952=ErrorMgr_Error_SysIntFault_USS_SENSOR9_DRVS_FAILURE_DURING_BURST, 953=ErrorMgr_Error_SysIntFault_USS_SENSOR9_NOISE_DURING_BURST, 954=ErrorMgr_Error_SysIntFault_USS_SENSOR9_DSP_Config_register_mismatch, 955=ErrorMgr_Error_SysIntFault_USS_SENSOR9_CPU_Config_register_mismatch, 956=ErrorMgr_Error_SysIntFault_USS_SENSOR9_RECEIVED_COMMAND_INVALID, 957=ErrorMgr_Error_SysIntFault_USS_SENSOR9_WD_COUNTER_DESYNC, 958=ErrorMgr_Error_SysIntFault_USS_SENSOR9_WD_CLOCK_FAIL, 959=ErrorMgr_Error_SysIntFault_USS_SENSOR9_SYNCHRONISATION_COUNTER_ERROR_DETECTED, 960=ErrorMgr_Error_SysIntFault_USS_SENSOR9_GET_DRV_FREQUENCY_FAILURE, 961=ErrorMgr_Error_SysIntFault_USS_SENSOR9_RING_COMPARATOR_ZERO, 962=ErrorMgr_Error_SysIntFault_USS_SENSOR9_VTANK_overvoltage_burst_status_failure, 963=ErrorMgr_Error_SysIntFault_USS_SENSOR9_BURST_ABORT_DURING_BURST, 964=ErrorMgr_Error_SysIntFault_USS_SENSOR9_VTANK_OVERVOLTAGE, 965=ErrorMgr_Error_SysIntFault_USS_SENSOR9_VTANK_UNDERVOLTAGE, 966=ErrorMgr_Error_SysIntFault_USS_SENSOR9_VSUP_OVER_VOLTAGE, 967=ErrorMgr_Error_SysIntFault_USS_SENSOR9_VSUP_UNDER_VOLTAGE, 968=ErrorMgr_Error_SysIntFault_USS_SENSOR9_Temparature_out_of_range_error, 969=ErrorMgr_Error_SysIntFault_USS_SENSOR9_SRAM_Parity_error, 970=ErrorMgr_Error_SysIntFault_USS_SENSOR9_CRC_BLOCK_CFG1, 971=ErrorMgr_Error_SysIntFault_USS_SENSOR9_CRC_BLOCK_CFG2, 972=ErrorMgr_Error_SysIntFault_USS_SENSOR9_CRC_BLOCK_MFG1, 973=ErrorMgr_Error_SysIntFault_USS_SENSOR9_CRC_BLOCK_MFG2, 974=ErrorMgr_Error_SysIntFault_USS_SENSOR9_CRC_OP_MODE1, 975=ErrorMgr_Error_SysIntFault_USS_SENSOR9_CRC_OP_MODE2, 976=ErrorMgr_Error_SysIntFault_USS_SENSOR9_CRC_MISMATCH_IN_OTP, 977=ErrorMgr_Error_SysIntFault_USS_SENSOR9_CRC_MISTMATCH_IN_EEPROM_A1, 978=ErrorMgr_Error_SysIntFault_USS_SENSOR9_CRC_MISTMATCH_IN_EEPROM_A2, 979=ErrorMgr_Error_SysIntFault_USS_SENSOR9_BAD_RING_TIME, 980=ErrorMgr_Error_SysIntFault_USS_SENSOR9_SNR_OPMODE_ERROR, 981=ErrorMgr_Error_SysIntFault_USS_SENSOR9_SNR_SETUP_SENSOR_FAIL, 982=ErrorMgr_Error_SysIntFault_USS_SENSOR9_GET_RING_FREQUENCY_FAILURE, 983=ErrorMgr_Error_SysIntFault_USS_SENSOR9_ADA_MEASURE_TIMEOUT, 984=ErrorMgr_Error_SysIntFault_USS_SENSOR9_PROGRAM_EEPROM, 985=ErrorMgr_Error_SysIntFault_USS_SENSOR10_FLG_SIGNAL_PATH_FAILURE, 986=ErrorMgr_Error_SysIntFault_USS_SENSOR10_Vref_out_of_range, 987=ErrorMgr_Error_SysIntFault_USS_SENSOR10_VREF_OTP_out_of_range, 988=ErrorMgr_Error_SysIntFault_USS_SENSOR10_VDDD_out_of_range, 989=ErrorMgr_Error_SysIntFault_USS_SENSOR10_DRV1_FAILURE_DURING_BURST, 990=ErrorMgr_Error_SysIntFault_USS_SENSOR10_DRV2_FAILURE_DURING_BURST, 991=ErrorMgr_Error_SysIntFault_USS_SENSOR10_DRVS_FAILURE_DURING_BURST, 992=ErrorMgr_Error_SysIntFault_USS_SENSOR10_NOISE_DURING_BURST, 993=ErrorMgr_Error_SysIntFault_USS_SENSOR10_DSP_Config_register_mismatch, 994=ErrorMgr_Error_SysIntFault_USS_SENSOR10_CPU_Config_register_mismatch, 995=ErrorMgr_Error_SysIntFault_USS_SENSOR10_RECEIVED_COMMAND_INVALID, 996=ErrorMgr_Error_SysIntFault_USS_SENSOR10_WD_COUNTER_DESYNC, 997=ErrorMgr_Error_SysIntFault_USS_SENSOR10_WD_CLOCK_FAIL, 998=ErrorMgr_Error_SysIntFault_USS_SENSOR10_SYNCHRONISATION_COUNTER_ERROR_DETECTED, 999=ErrorMgr_Error_SysIntFault_USS_SENSOR10_GET_DRV_FREQUENCY_FAILURE, 1000=ErrorMgr_Error_SysIntFault_USS_SENSOR10_RING_COMPARATOR_ZERO, 1001=ErrorMgr_Error_SysIntFault_USS_SENSOR10_VTANK_overvoltage_burst_status_failure, 1002=ErrorMgr_Error_SysIntFault_USS_SENSOR10_BURST_ABORT_DURING_BURST, 1003=ErrorMgr_Error_SysIntFault_USS_SENSOR10_VTANK_OVERVOLTAGE, 1004=ErrorMgr_Error_SysIntFault_USS_SENSOR10_VTANK_UNDERVOLTAGE, 1005=ErrorMgr_Error_SysIntFault_USS_SENSOR10_VSUP_OVER_VOLTAGE, 1006=ErrorMgr_Error_SysIntFault_USS_SENSOR10_VSUP_UNDER_VOLTAGE, 1007=ErrorMgr_Error_SysIntFault_USS_SENSOR10_Temparature_out_of_range_error, 1008=ErrorMgr_Error_SysIntFault_USS_SENSOR10_SRAM_Parity_error, 1009=ErrorMgr_Error_SysIntFault_USS_SENSOR10_CRC_BLOCK_CFG1, 1010=ErrorMgr_Error_SysIntFault_USS_SENSOR10_CRC_BLOCK_CFG2, 1011=ErrorMgr_Error_SysIntFault_USS_SENSOR10_CRC_BLOCK_MFG1, 1012=ErrorMgr_Error_SysIntFault_USS_SENSOR10_CRC_BLOCK_MFG2, 1013=ErrorMgr_Error_SysIntFault_USS_SENSOR10_CRC_OP_MODE1, 1014=ErrorMgr_Error_SysIntFault_USS_SENSOR10_CRC_OP_MODE2, 1015=ErrorMgr_Error_SysIntFault_USS_SENSOR10_CRC_MISMATCH_IN_OTP, 1016=ErrorMgr_Error_SysIntFault_USS_SENSOR10_CRC_MISTMATCH_IN_EEPROM_A1, 1017=ErrorMgr_Error_SysIntFault_USS_SENSOR10_CRC_MISTMATCH_IN_EEPROM_A2, 1018=ErrorMgr_Error_SysIntFault_USS_SENSOR10_BAD_RING_TIME, 1019=ErrorMgr_Error_SysIntFault_USS_SENSOR10_SNR_OPMODE_ERROR, 1020=ErrorMgr_Error_SysIntFault_USS_SENSOR10_SNR_SETUP_SENSOR_FAIL, 1021=ErrorMgr_Error_SysIntFault_USS_SENSOR10_GET_RING_FREQUENCY_FAILURE, 1022=ErrorMgr_Error_SysIntFault_USS_SENSOR10_ADA_MEASURE_TIMEOUT, 1023=ErrorMgr_Error_SysIntFault_USS_SENSOR10_PROGRAM_EEPROM, 1024=ErrorMgr_Error_SysIntFault_USS_SENSOR11_FLG_SIGNAL_PATH_FAILURE, 1025=ErrorMgr_Error_SysIntFault_USS_SENSOR11_Vref_out_of_range, 1026=ErrorMgr_Error_SysIntFault_USS_SENSOR11_VREF_OTP_out_of_range, 1027=ErrorMgr_Error_SysIntFault_USS_SENSOR11_VDDD_out_of_range, 1028=ErrorMgr_Error_SysIntFault_USS_SENSOR11_DRV1_FAILURE_DURING_BURST, 1029=ErrorMgr_Error_SysIntFault_USS_SENSOR11_DRV2_FAILURE_DURING_BURST, 1030=ErrorMgr_Error_SysIntFault_USS_SENSOR11_DRVS_FAILURE_DURING_BURST, 1031=ErrorMgr_Error_SysIntFault_USS_SENSOR11_NOISE_DURING_BURST, 1032=ErrorMgr_Error_SysIntFault_USS_SENSOR11_DSP_Config_register_mismatch, 1033=ErrorMgr_Error_SysIntFault_USS_SENSOR11_CPU_Config_register_mismatch, 1034=ErrorMgr_Error_SysIntFault_USS_SENSOR11_RECEIVED_COMMAND_INVALID, 1035=ErrorMgr_Error_SysIntFault_USS_SENSOR11_WD_COUNTER_DESYNC, 1036=ErrorMgr_Error_SysIntFault_USS_SENSOR11_WD_CLOCK_FAIL, 1037=ErrorMgr_Error_SysIntFault_USS_SENSOR11_SYNCHRONISATION_COUNTER_ERROR_DETECTED, 1038=ErrorMgr_Error_SysIntFault_USS_SENSOR11_GET_DRV_FREQUENCY_FAILURE, 1039=ErrorMgr_Error_SysIntFault_USS_SENSOR11_RING_COMPARATOR_ZERO, 1040=ErrorMgr_Error_SysIntFault_USS_SENSOR11_VTANK_overvoltage_burst_status_failure, 1041=ErrorMgr_Error_SysIntFault_USS_SENSOR11_BURST_ABORT_DURING_BURST, 1042=ErrorMgr_Error_SysIntFault_USS_SENSOR11_VTANK_OVERVOLTAGE, 1043=ErrorMgr_Error_SysIntFault_USS_SENSOR11_VTANK_UNDERVOLTAGE, 1044=ErrorMgr_Error_SysIntFault_USS_SENSOR11_VSUP_OVER_VOLTAGE, 1045=ErrorMgr_Error_SysIntFault_USS_SENSOR11_VSUP_UNDER_VOLTAGE, 1046=ErrorMgr_Error_SysIntFault_USS_SENSOR11_Temparature_out_of_range_error, 1047=ErrorMgr_Error_SysIntFault_USS_SENSOR11_SRAM_Parity_error, 1048=ErrorMgr_Error_SysIntFault_USS_SENSOR11_CRC_BLOCK_CFG1, 1049=ErrorMgr_Error_SysIntFault_USS_SENSOR11_CRC_BLOCK_CFG2, 1050=ErrorMgr_Error_SysIntFault_USS_SENSOR11_CRC_BLOCK_MFG1, 1051=ErrorMgr_Error_SysIntFault_USS_SENSOR11_CRC_BLOCK_MFG2, 1052=ErrorMgr_Error_SysIntFault_USS_SENSOR11_CRC_OP_MODE1, 1053=ErrorMgr_Error_SysI}, implementation-data-type=uint32
    ErrorMgr_enSafeStates: compu {0=ErrorMgr_SafeState_safestate1, 1=ErrorMgr_SafeState_safestate16, 2=ErrorMgr_SafeState_safestate23, 3=ErrorMgr_SafeState_safestate24, 4=ErrorMgr_SafeState_safestate17, 5=ErrorMgr_SafeState_safestate13, 6=ErrorMgr_SafeState_safestate12, 7=ErrorMgr_SafeState_safestate9, 8=ErrorMgr_SafeState_safestate10, 9=ErrorMgr_SafeState_safestate7, 10=ErrorMgr_SafeState_safestate4, 11=ErrorMgr_SafeState_safestate2, 12=ErrorMgr_SafeState_safestate5, 13=ErrorMgr_SafeState_safestate11, 14=ErrorMgr_SafeState_safestate21, 15=ErrorMgr_SafeState_Max}, implementation-data-type=uint32
    ErrorMgr_enErrorStatus: compu {0=ErrorMgr_Invalid, 1=ErrorMgr_ErrorInactive, 2=ErrorMgr_ErrorActive}, implementation-data-type=uint32
    ErrorMgr_ErrorCommPack_1_0_B: category=STRUCTURE
      4 x element, all with category=TYPE_REFERENCE:
        RunningCounter: implementation-data-type=uint32
        Checksum: implementation-data-type=uint32
        Error: implementation-data-type=Error1_0B_arr
        Data: implementation-data-type=Data1_0B_arr
    ErrorMgr_ErrorCommPack_2_0_B: category=STRUCTURE
      4 x element, all with category=TYPE_REFERENCE:
        RunningCounter: implementation-data-type=uint32
        Checksum: implementation-data-type=uint32
        Error: implementation-data-type=Error2_0B_arr
        Data: implementation-data-type=Data2_0B_arr
    ErrorMgr_ErrorCommPack_2_1_B: category=STRUCTURE
      4 x element, all with category=TYPE_REFERENCE:
        RunningCounter: implementation-data-type=uint32
        Checksum: implementation-data-type=uint32
        Error: implementation-data-type=Error2_1B_arr
        Data: implementation-data-type=Data2_1B_arr
    ErrorMgr_ErrorCommPack_QNX_B: category=STRUCTURE
      4 x element, all with category=TYPE_REFERENCE:
        RunningCounter: implementation-data-type=uint32
        Checksum: implementation-data-type=uint32
        Error: implementation-data-type=ErrorQNXB_arr
        Data: implementation-data-type=DataQNXB_arr
    ErrorMgr_stAddData: category=STRUCTURE
      element AdditionalData: implementation-data-type=AdditionalData_arr
package /Pkg_ErrorMgrSat_2_1_B/PortInterfaces
  client server interface P_Error_CS
    operation ReportErrorStatus2_1_B: possible-error=E_NOK
      arg err: type=ErrorMgr_enErrorNo, direction=IN, server-argument-impl-policy=USE-ARGUMENT-TYPE
      arg errStatus: type=ErrorMgr_enErrorStatus, direction=IN, server-argument-impl-policy=USE-ARGUMENT-TYPE
      arg addData: type=ErrorMgr_stAddData, direction=IN, server-argument-impl-policy=USE-ARGUMENT-TYPE
    error E_NOK: error-code=1
